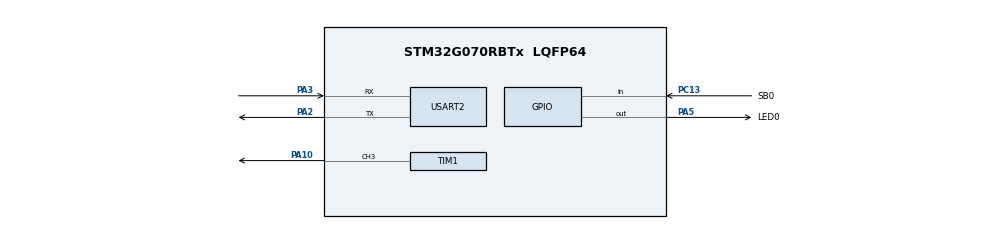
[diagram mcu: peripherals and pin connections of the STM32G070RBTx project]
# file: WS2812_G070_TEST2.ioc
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Dma.Request0=TIM1_CH3
Dma.TIM1_CH3.0.Direction=DMA_MEMORY_TO_PERIPH
Dma.TIM1_CH3.0.EventEnable=DISABLE
Dma.TIM1_CH3.0.Instance=DMA1_Channel7
Dma.TIM1_CH3.0.MemDataAlignment=DMA_MDATAALIGN_BYTE
Dma.TIM1_CH3.0.MemInc=DMA_MINC_ENABLE
Dma.TIM1_CH3.0.Mode=DMA_NORMAL
Dma.TIM1_CH3.0.PeriphDataAlignment=DMA_PDATAALIGN_WORD
Dma.TIM1_CH3.0.PeriphInc=DMA_PINC_DISABLE
Dma.TIM1_CH3.0.Polarity=HAL_DMAMUX_REQ_GEN_RISING
Dma.TIM1_CH3.0.Priority=DMA_PRIORITY_HIGH
Dma.TIM1_CH3.0.RequestNumber=1
Dma.TIM1_CH3.0.SignalID=NONE
Dma.TIM1_CH3.0.SyncEnable=DISABLE
Dma.TIM1_CH3.0.SyncPolarity=HAL_DMAMUX_SYNC_NO_EVENT
Dma.TIM1_CH3.0.SyncRequestNumber=1
Dma.TIM1_CH3.0.SyncSignalID=NONE
Mcu.Family=STM32G0
Mcu.Name=STM32G070RBTx
Mcu.Package=LQFP64
NVIC.DMA1_Ch4_7_DMAMUX1_OVR_IRQn=true\:0\:0\:false\:false\:true\:false\:true
PA10.Signal=S_TIM1_CH3
PA13.GPIO_Label=TMS
PA13.Mode=Serial_Wire
PA13.Signal=SYS_SWDIO
PA14-BOOT0.GPIO_Label=TCK
PA14-BOOT0.Mode=Serial_Wire
PA14-BOOT0.Signal=SYS_SWCLK
PA2.Mode=Asynchronous
PA2.Signal=USART2_TX
PA3.Mode=Asynchronous
PA3.Signal=USART2_RX
PA5.GPIO_Label=LED0
PA5.GPIO_Speed=GPIO_SPEED_FREQ_MEDIUM
PA5.Signal=GPIO_Output
PC13.GPIO_Label=SB0
PC13.GPIO_PuPd=GPIO_PULLUP
PC13.Signal=GPIO_Input
PC14-OSC32_IN\ (PC14).Mode=LSE-External-Oscillator
PC14-OSC32_IN\ (PC14).Signal=RCC_OSC32_IN
PC15-OSC32_OUT\ (PC15).Mode=LSE-External-Oscillator
PC15-OSC32_OUT\ (PC15).Signal=RCC_OSC32_OUT
PF0-OSC_IN\ (PF0).GPIO_Label=MCO
PF0-OSC_IN\ (PF0).Mode=HSE-External-Clock-Source
PF0-OSC_IN\ (PF0).Signal=RCC_OSC_IN
ProjectManager.HeapSize=0x200
ProjectManager.StackSize=0x400
ProjectManager.TargetToolchain=MDK-ARM V5.27
RCC.ADCFreq_Value=64000000
RCC.AHBFreq_Value=64000000
RCC.CortexFreq_Value=64000000
RCC.EXTERNAL_CLOCK_VALUE=12288000
RCC.HCLKFreq_Value=64000000
RCC.HSE_VALUE=8000000
RCC.HSI_VALUE=16000000
RCC.SYSCLKFreq_VALUE=64000000
RCC.SYSCLKSource=RCC_SYSCLKSOURCE_PLLCLK
RCC.VCOOutputFreq_Value=128000000
SH.S_TIM1_CH3.0=TIM1_CH3,PWM Generation3 CH3
TIM1.Channel-PWM\ Generation3\ CH3=TIM_CHANNEL_3
TIM1.OC3Preload_PWM=DISABLE
TIM1.Period=79
USART2.VirtualMode-Asynchronous=VM_ASYNC
VP_SYS_VS_DBSignals.Mode=DisableDeadBatterySignals
VP_TIM1_VS_ClockSourceINT.Mode=Internal
board=NUCLEO-G070RB

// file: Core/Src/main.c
/* USER CODE BEGIN Header */
/**
  ******************************************************************************
  * @file           : main.c
  * @brief          : Main program body
  ******************************************************************************
  * @attention
  *
  * <h2><center>&copy; Copyright (c) 2020 STMicroelectronics.
  * All rights reserved.</center></h2>
  *
  * This software component is licensed by ST under BSD 3-Clause license,
  * the "License"; You may not use this file except in compliance with the
  * License. You may obtain a copy of the License at:
  *                        opensource.org/licenses/BSD-3-Clause
  *
  ******************************************************************************
  */
/* USER CODE END Header */

#include "main.h"
#include "dma.h"
#include "tim.h"
#include "usart.h"
#include "gpio.h"

/* USER CODE BEGIN Includes */
#include "bsp_ws2812.h"
/* USER CODE END Includes */

void SystemClock_Config(void);

int main(void)
{

  /* MCU Configuration--------------------------------------------------------*/

  /* Reset of all peripherals, Initializes the Flash interface and the Systick. */

  LL_APB2_GRP1_EnableClock(LL_APB2_GRP1_PERIPH_SYSCFG);
  LL_APB1_GRP1_EnableClock(LL_APB1_GRP1_PERIPH_PWR);

  /* System interrupt init*/

  /* Configure the system clock */
  SystemClock_Config();

  /* Initialize all configured peripherals */
  MX_GPIO_Init();
  MX_DMA_Init();
  MX_TIM1_Init();
  MX_USART2_UART_Init();
  /* USER CODE BEGIN 2 */

    LL_GPIO_TogglePin ( LED0_GPIO_Port, LED0_Pin );
    LL_mDelay ( 1000 );
    LL_GPIO_TogglePin ( LED0_GPIO_Port, LED0_Pin );
  /* USER CODE END 2 */

  /* Infinite loop */
  /* USER CODE BEGIN WHILE */
    while ( 1 )
    {
        WS281x_ColorWipe(30, 100);
        WS281x_ColorWipe(30 << 8, 100);
        WS281x_ColorWipe(30 << 16, 100);
        WS281x_TheaterChaseRainbow ( 20 );
    /* USER CODE END WHILE */

    }
}

void SystemClock_Config(void)
{
  LL_FLASH_SetLatency(LL_FLASH_LATENCY_2);
  if(LL_FLASH_GetLatency() != LL_FLASH_LATENCY_2)
  {
    Error_Handler();
  };

  /* HSI configuration and activation */
  LL_RCC_HSI_Enable();
  while(LL_RCC_HSI_IsReady() != 1)
  {
  };

  /* Main PLL configuration and activation */
  LL_RCC_PLL_ConfigDomain_SYS(LL_RCC_PLLSOURCE_HSI, LL_RCC_PLLM_DIV_1, 8, LL_RCC_PLLR_DIV_2);
  LL_RCC_PLL_Enable();
  LL_RCC_PLL_EnableDomain_SYS();
  while(LL_RCC_PLL_IsReady() != 1)
  {
  };

  /* Set AHB prescaler*/
  LL_RCC_SetAHBPrescaler(LL_RCC_SYSCLK_DIV_1);

  /* Sysclk activation on the main PLL */
  LL_RCC_SetSysClkSource(LL_RCC_SYS_CLKSOURCE_PLL);
  while(LL_RCC_GetSysClkSource() != LL_RCC_SYS_CLKSOURCE_STATUS_PLL)
  {
  };

  /* Set APB1 prescaler*/
  LL_RCC_SetAPB1Prescaler(LL_RCC_APB1_DIV_1);
  LL_Init1msTick(64000000);
  LL_SYSTICK_SetClkSource(LL_SYSTICK_CLKSOURCE_HCLK);
  LL_SetSystemCoreClock(64000000);
  /* Update CMSIS variable (which can be updated also through SystemCoreClockUpdate function) */
  LL_SetSystemCoreClock(64000000);
  LL_RCC_SetUSARTClockSource(LL_RCC_USART2_CLKSOURCE_PCLK1);
}

void Error_Handler(void)
{
    while ( 1 )
    {
    }
}

/************************ (C) COPYRIGHT STMicroelectronics *****END OF FILE****/
